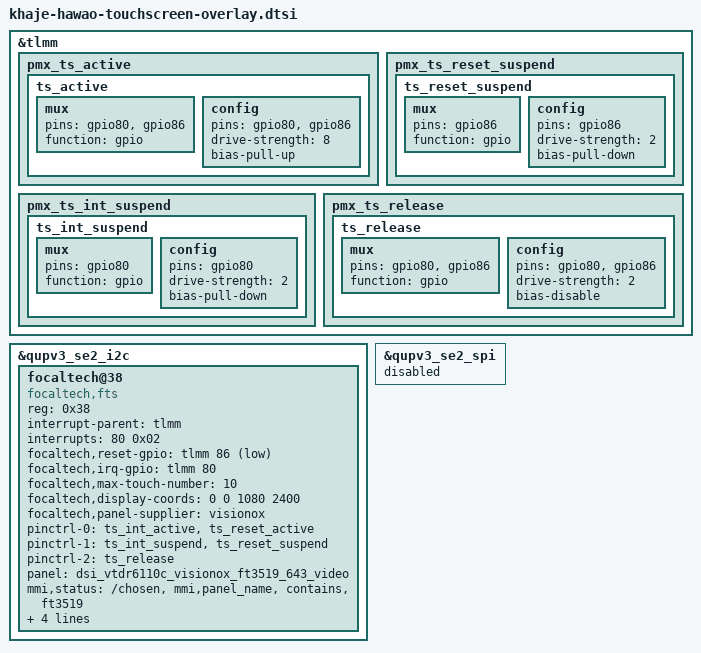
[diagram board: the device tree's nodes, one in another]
&tlmm{
		pmx_ts_active {
			ts_active: ts_active {
				mux {
					pins = "gpio80", "gpio86";
					function = "gpio";
				};

				config {
					pins = "gpio80", "gpio86";
					drive-strength = <8>;
					bias-pull-up;
				};
			};
		};

		pmx_ts_reset_suspend {
			ts_reset_suspend: ts_reset_suspend {
				mux {
					pins = "gpio86";
					function = "gpio";
				};

				config {
					pins = "gpio86";
					drive-strength = <2>;
					bias-pull-down;
				};
			};
		};

		pmx_ts_int_suspend {
			ts_int_suspend: ts_int_suspend {
				mux {
					pins = "gpio80";
					function = "gpio";
				};

				config {
					pins = "gpio80";
					drive-strength = <2>;
					bias-pull-down;
				};
			};
		};

		pmx_ts_release {
			ts_release: ts_release {
				mux {
					pins = "gpio80", "gpio86";
					function = "gpio";
				};

				config {
					pins = "gpio80", "gpio86";
					drive-strength = <2>;
					bias-disable;
				};
			};
		};
};

&qupv3_se2_i2c {
	status = "okay";
	focaltech@38{
		compatible = "focaltech,fts";
		reg = <0x38>;
		interrupt-parent = <&tlmm>;
		interrupts = <80 0x02>;
		focaltech,reset-gpio = <&tlmm 86 0x01>;
		focaltech,irq-gpio = <&tlmm 80 0x02>;
		focaltech,max-touch-number = <10>;
		focaltech,display-coords =  <0 0 1080 2400>;
		focaltech,panel-supplier = "visionox";

		pinctrl-names = "pmx_ts_active","pmx_ts_suspend","pmx_ts_release";
		pinctrl-0 = <&ts_int_active &ts_reset_active>;
		pinctrl-1 = <&ts_int_suspend &ts_reset_suspend>;
		pinctrl-2 = <&ts_release>;

		panel = <&dsi_vtdr6110c_visionox_ft3519_643_video>;
		//touchscreen_mmi
		mmi,status = "/chosen","mmi,panel_name","contains","ft3519";
		mmi,class-entry-name = "ft3519";
		mmi,reset-on-resume = <0x01>;
		mmi,enable-gestures;
		mmi,usb-charger-detection;

	};
};

&qupv3_se2_spi {
	#address-cells = <1>;
	#size-cells = <0>;

	status = "disabled";

};

